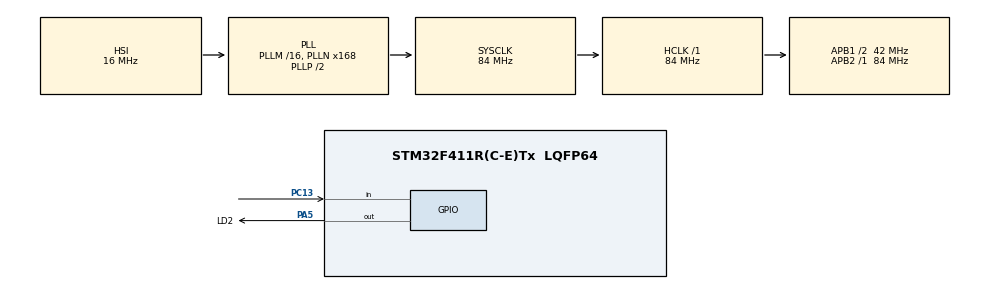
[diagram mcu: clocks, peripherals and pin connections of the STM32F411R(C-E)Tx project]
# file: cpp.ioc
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Mcu.Family=STM32F4
Mcu.Name=STM32F411R(C-E)Tx
Mcu.Package=LQFP64
NVIC.PriorityGroup=NVIC_PRIORITYGROUP_4
NVIC.TIM4_IRQn=true\:15\:0\:false\:false\:true\:false\:true\:true
NVIC.TimeBase=TIM4_IRQn
NVIC.TimeBaseIP=TIM4
PA2.Signal=USART2_TX
PA3.Signal=USART2_RX
PA5.GPIO_Label=LD2
PA5.Signal=GPIO_Output
PC13-ANTI_TAMP.Signal=GPIO_Input
ProjectManager.HeapSize=0x200
ProjectManager.StackSize=0x400
ProjectManager.TargetToolchain=STM32CubeIDE
RCC.48MHZClocksFreq_Value=42000000
RCC.AHBFreq_Value=84000000
RCC.APB1CLKDivider=RCC_HCLK_DIV2
RCC.APB1Freq_Value=42000000
RCC.APB1TimFreq_Value=84000000
RCC.APB2Freq_Value=84000000
RCC.APB2TimFreq_Value=84000000
RCC.CortexFreq_Value=84000000
RCC.HCLKFreq_Value=84000000
RCC.HSE_VALUE=25000000
RCC.HSI_VALUE=16000000
RCC.LSE_VALUE=32768
RCC.PLLN=168
RCC.SYSCLKFreq_VALUE=84000000
RCC.SYSCLKSource=RCC_SYSCLKSOURCE_PLLCLK
RCC.VCOOutputFreq_Value=168000000
VP_SYS_VS_tim4.Mode=TIM4
board=custom

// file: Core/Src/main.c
/* USER CODE BEGIN Header */
/**
 ******************************************************************************
 * @file           : main.c
 * @brief          : Main program body
 ******************************************************************************
 * @attention
 *
 * Copyright (c) 2024 STMicroelectronics.
 * All rights reserved.
 *
 * This software is licensed under terms that can be found in the LICENSE file
 * in the root directory of this software component.
 * If no LICENSE file comes with this software, it is provided AS-IS.
 *
 ******************************************************************************
 */
/* USER CODE END Header */
#include "main.h"

/* USER CODE BEGIN Includes */
#include <stdio.h>
#include "FreeRTOS.h"
#include "task.h"
#include "semphr.h"
#include "queue.h"
/* USER CODE END Includes */

/* USER CODE BEGIN PV */
#define DWT_CTRL          (*((volatile uint32_t *) 0xE0001000))
/* USER CODE END PV */

void SystemClock_Config(void);
static void MX_GPIO_Init(void);
/* USER CODE BEGIN PFP */
SemaphoreHandle_t xSemaphore1;
SemaphoreHandle_t xSemaphore2;

TaskHandle_t task1_handle;
TaskHandle_t task2_handle;
TaskHandle_t task3_handle;
TaskHandle_t btn_handle;

void SEGGER_UART_init(U32 baud);
static void task1_handler(void *param);
static void task2_handler(void *param);
static void task3_handler(void *param);
static void btn_handler(void *param);

volatile TaskHandle_t nxt_del_handle;
/* USER CODE END PFP */

int main(void) {

	/* USER CODE BEGIN 1 */

	BaseType_t status;
	/* USER CODE END 1 */

	/* MCU Configuration--------------------------------------------------------*/

	/* Reset of all peripherals, Initializes the Flash interface and the Systick. */
	HAL_Init();

	/* Configure the system clock */
	SystemClock_Config();

	/* Initialize all configured peripherals */
	MX_GPIO_Init();
	/* USER CODE BEGIN 2 */
	// Enable CYCCNT counter.
	DWT_CTRL |= (1 << 0);

	// Start SEGGER Uart (segger_uart.c)
	SEGGER_UART_init(921600);

	// Start SEGGER
	SEGGER_SYSVIEW_Conf();

	xSemaphore1 = xSemaphoreCreateMutex(4);
	xSemaphore2 = xSemaphoreCreateMutex(4);

	status = xTaskCreate(task1_handler, "task-1", 200, "task1: Turn on the led",
			3, &task1_handle);
	configASSERT(status == pdPASS);

	nxt_del_handle = task1_handle;

	status = xTaskCreate(task2_handler, "task-2", 200,
			"task2: Turn off the led", 2, &task2_handle);
	configASSERT(status == pdPASS);

//  status = xTaskCreate(task3_handler, "task-3", 200, "task3: Do nothing", 1, &task3_handle);
//  configASSERT(status == pdPASS);

//  status = xTaskCreate(btn_handler, "btn", 200, "Button Task: ", 4, &btn_handle);
//  configASSERT(status == pdPASS);

	vTaskStartScheduler();

	/* USER CODE END 2 */

	/* Infinite loop */
	while (1) {

	}
}

void SystemClock_Config(void) {
	RCC_OscInitTypeDef RCC_OscInitStruct = { 0 };
	RCC_ClkInitTypeDef RCC_ClkInitStruct = { 0 };

	/** Configure the main internal regulator output voltage
	 */
	__HAL_RCC_PWR_CLK_ENABLE();
	__HAL_PWR_VOLTAGESCALING_CONFIG(PWR_REGULATOR_VOLTAGE_SCALE1);

	/** Initializes the RCC Oscillators according to the specified parameters
	 * in the RCC_OscInitTypeDef structure.
	 */
	RCC_OscInitStruct.OscillatorType = RCC_OSCILLATORTYPE_HSI;
	RCC_OscInitStruct.HSIState = RCC_HSI_ON;
	RCC_OscInitStruct.HSICalibrationValue = RCC_HSICALIBRATION_DEFAULT;
	RCC_OscInitStruct.PLL.PLLState = RCC_PLL_ON;
	RCC_OscInitStruct.PLL.PLLSource = RCC_PLLSOURCE_HSI;
	RCC_OscInitStruct.PLL.PLLM = 16;
	RCC_OscInitStruct.PLL.PLLN = 168;
	RCC_OscInitStruct.PLL.PLLP = RCC_PLLP_DIV2;
	RCC_OscInitStruct.PLL.PLLQ = 4;
	if (HAL_RCC_OscConfig(&RCC_OscInitStruct) != HAL_OK) {
		Error_Handler();
	}

	/** Initializes the CPU, AHB and APB buses clocks
	 */
	RCC_ClkInitStruct.ClockType = RCC_CLOCKTYPE_HCLK | RCC_CLOCKTYPE_SYSCLK
			| RCC_CLOCKTYPE_PCLK1 | RCC_CLOCKTYPE_PCLK2;
	RCC_ClkInitStruct.SYSCLKSource = RCC_SYSCLKSOURCE_PLLCLK;
	RCC_ClkInitStruct.AHBCLKDivider = RCC_SYSCLK_DIV1;
	RCC_ClkInitStruct.APB1CLKDivider = RCC_HCLK_DIV2;
	RCC_ClkInitStruct.APB2CLKDivider = RCC_HCLK_DIV1;

	if (HAL_RCC_ClockConfig(&RCC_ClkInitStruct, FLASH_LATENCY_2) != HAL_OK) {
		Error_Handler();
	}
}

static void MX_GPIO_Init(void) {
	GPIO_InitTypeDef GPIO_InitStruct = { 0 };

	/* GPIO Ports Clock Enable */
	__HAL_RCC_GPIOC_CLK_ENABLE();
	__HAL_RCC_GPIOA_CLK_ENABLE();

	/*Configure GPIO pin Output Level */
	HAL_GPIO_WritePin(LD2_GPIO_Port, LD2_Pin, GPIO_PIN_RESET);

	/*Configure GPIO pin : PC13 */
	GPIO_InitStruct.Pin = GPIO_PIN_13;
	GPIO_InitStruct.Mode = GPIO_MODE_INPUT;
	GPIO_InitStruct.Pull = GPIO_NOPULL;
	HAL_GPIO_Init(GPIOC, &GPIO_InitStruct);

	/*Configure GPIO pins : PA2 PA3 */
	GPIO_InitStruct.Pin = GPIO_PIN_2 | GPIO_PIN_3;
	GPIO_InitStruct.Mode = GPIO_MODE_AF_PP;
	GPIO_InitStruct.Pull = GPIO_NOPULL;
	GPIO_InitStruct.Speed = GPIO_SPEED_FREQ_VERY_HIGH;
	GPIO_InitStruct.Alternate = GPIO_AF7_USART2;
	HAL_GPIO_Init(GPIOA, &GPIO_InitStruct);

	/*Configure GPIO pin : LD2_Pin */
	GPIO_InitStruct.Pin = LD2_Pin;
	GPIO_InitStruct.Mode = GPIO_MODE_OUTPUT_PP;
	GPIO_InitStruct.Pull = GPIO_NOPULL;
	GPIO_InitStruct.Speed = GPIO_SPEED_FREQ_LOW;
	HAL_GPIO_Init(LD2_GPIO_Port, &GPIO_InitStruct);

}

/* USER CODE BEGIN 4 */
static void task1_handler(void *param) {

	while (1) {
		vTaskDelay(pdMS_TO_TICKS(5000));
		// Delay 1000 ms
		SEGGER_SYSVIEW_PrintfTarget("Task1 delay 5000 ms\n");
		vTaskDelay(pdMS_TO_TICKS(5000));

		SEGGER_SYSVIEW_PrintfTarget("Task1 compute 2000 ms\n");
		HAL_Delay(2000);

		SEGGER_SYSVIEW_PrintfTarget("Task1 take semaphore 2\n");
		if ( xSemaphoreTake(xSemaphore2,
				( TickType_t ) pdMS_TO_TICKS(10000)) == pdTRUE) {
			SEGGER_SYSVIEW_PrintfTarget("Task1 compute 3000 ms: R2\n");
			HAL_Delay(3000);

			//Take xSemaphore1
			SEGGER_SYSVIEW_PrintfTarget("Task1 take semaphore 1\n");
			if ( xSemaphoreTake(xSemaphore1,
					(TickType_t) pdMS_TO_TICKS(10000)) == pdTRUE) {
				SEGGER_SYSVIEW_PrintfTarget("Task1 compute 3000 ms: R1, R2\n");
				HAL_Delay(3000);

				SEGGER_SYSVIEW_PrintfTarget("Task1 give semaphore1\n");
				xSemaphoreGive(xSemaphore1);
			} else {
				SEGGER_SYSVIEW_PrintfTarget("Task1 fail taking semaphore 1\n");
			}

			SEGGER_SYSVIEW_PrintfTarget("Task1 compute 3000 ms: R2\n");
			HAL_Delay(3000);

			xSemaphoreGive(xSemaphore2);
			SEGGER_SYSVIEW_PrintfTarget("Task1 give semaphore 2\n");
		} else {
			SEGGER_SYSVIEW_PrintfTarget("Task1 fail taking semaphore 2\n");
		}

		SEGGER_SYSVIEW_PrintfTarget("Task1 delay 10000 ms\n");
		vTaskDelay(pdMS_TO_TICKS(10000));
	}
}

static void task2_handler(void *param) {

	while (1) {
		vTaskDelay(pdMS_TO_TICKS(5000));
		SEGGER_SYSVIEW_PrintfTarget("Task2 compute 2000 ms\n");
		HAL_Delay(2000);

		SEGGER_SYSVIEW_PrintfTarget("Task2 take semaphore 1\n");
		if ( xSemaphoreTake(xSemaphore1,
				( TickType_t ) pdMS_TO_TICKS(10000)) == pdTRUE) {
			SEGGER_SYSVIEW_PrintfTarget("Task2 compute 6000 ms: R1\n");
			HAL_Delay(6000);

			// task2 take semaphore2
			SEGGER_SYSVIEW_PrintfTarget("Task2 take semaphore2\n");
			if ( xSemaphoreTake(xSemaphore2,
					( TickType_t ) pdMS_TO_TICKS(10000)) == pdTRUE) {
				SEGGER_SYSVIEW_PrintfTarget("Task2 compute 2000 ms: R1, R2\n");
				HAL_Delay(2000);

				SEGGER_SYSVIEW_PrintfTarget("Task2 give semaphore 2\n");
				xSemaphoreGive(xSemaphore2);
			} else {
				SEGGER_SYSVIEW_PrintfTarget("Task2 fail taking semaphore 2\n");
			}
			SEGGER_SYSVIEW_PrintfTarget("Task2 compute 2000 ms: R1\n");
			HAL_Delay(2000);

			SEGGER_SYSVIEW_PrintfTarget("Task2 give semaphore 1\n");
			xSemaphoreGive(xSemaphore1);
		} else {
			SEGGER_SYSVIEW_PrintfTarget("Task2 fail taking semaphore 1\n");
		}

		SEGGER_SYSVIEW_PrintfTarget("Task2 delay 1000 ms\n");
		vTaskDelay(pdMS_TO_TICKS(1000));
	}
}

static void task3_handler(void *param) {
	BaseType_t status;

	while (1) {
		SEGGER_SYSVIEW_PrintfTarget("Task 3\n");
		status = xTaskNotifyWait(0, 0, NULL, pdMS_TO_TICKS(1000));
		if (status == pdTRUE) {
			vTaskSuspendAll();
			nxt_del_handle = btn_handle;
			xTaskResumeAll();
			vTaskSuspend(NULL);
		}
	}
}

static void btn_handler(void *param) {
	uint8_t btn_read = 0;
	uint8_t prev_read = 1;

	btn_read = HAL_GPIO_ReadPin(BTN_GPIO_Port, BTN_Pin);
	vTaskDelay(pdMS_TO_TICKS(10));

	while (1) {
		btn_read = HAL_GPIO_ReadPin(BTN_GPIO_Port, BTN_Pin);

		if (btn_read) {
			if (!prev_read) {
				if (nxt_del_handle != btn_handle) {
					SEGGER_SYSVIEW_PrintfTarget("Notify a task to shutdown\n");
					xTaskNotify(nxt_del_handle, 0, eNoAction);
				} else {
					SEGGER_SYSVIEW_PrintfTarget("Resume all tasks\n");
					nxt_del_handle = task1_handle;
					vTaskResume(task1_handle);
					vTaskResume(task2_handle);
					vTaskResume(task3_handle);
				}
			}
		}

		prev_read = btn_read;
		vTaskDelay(pdMS_TO_TICKS(10)); // 每 10 ms 檢查一次
	}
}

/* USER CODE END 4 */

void HAL_TIM_PeriodElapsedCallback(TIM_HandleTypeDef *htim) {
	if (htim->Instance == TIM4) {
		HAL_IncTick();
	}
}

void Error_Handler(void) {
	__disable_irq();
	while (1) {
	}
}
